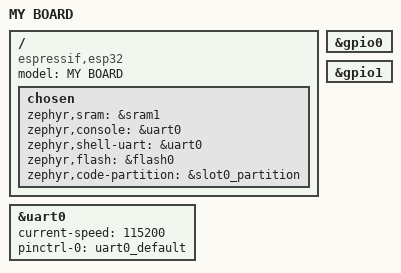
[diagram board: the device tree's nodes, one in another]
/*
 * Copyright (c) 2025
 *
 * SPDX-License-Identifier: Apache-2.0
 */

/dts-v1/;

#include <espressif/esp32/esp32_wrover_e_n4r8.dtsi>
#include "my_board-pinctrl.dtsi"
#include <espressif/partitions_0x1000_amp.dtsi>

/ {
	model = "MY BOARD";
	compatible = "espressif,esp32";

	chosen {
		zephyr,sram = &sram1;
		zephyr,console = &uart0;
		zephyr,shell-uart = &uart0;
		zephyr,flash = &flash0;
		zephyr,code-partition = &slot0_partition;
	};
};

&uart0 {
	status = "okay";
	current-speed = <115200>;
	pinctrl-0 = <&uart0_default>;
	pinctrl-names = "default";
};

&gpio0 {
	status = "okay";
};

&gpio1 {
	status = "okay";
};
